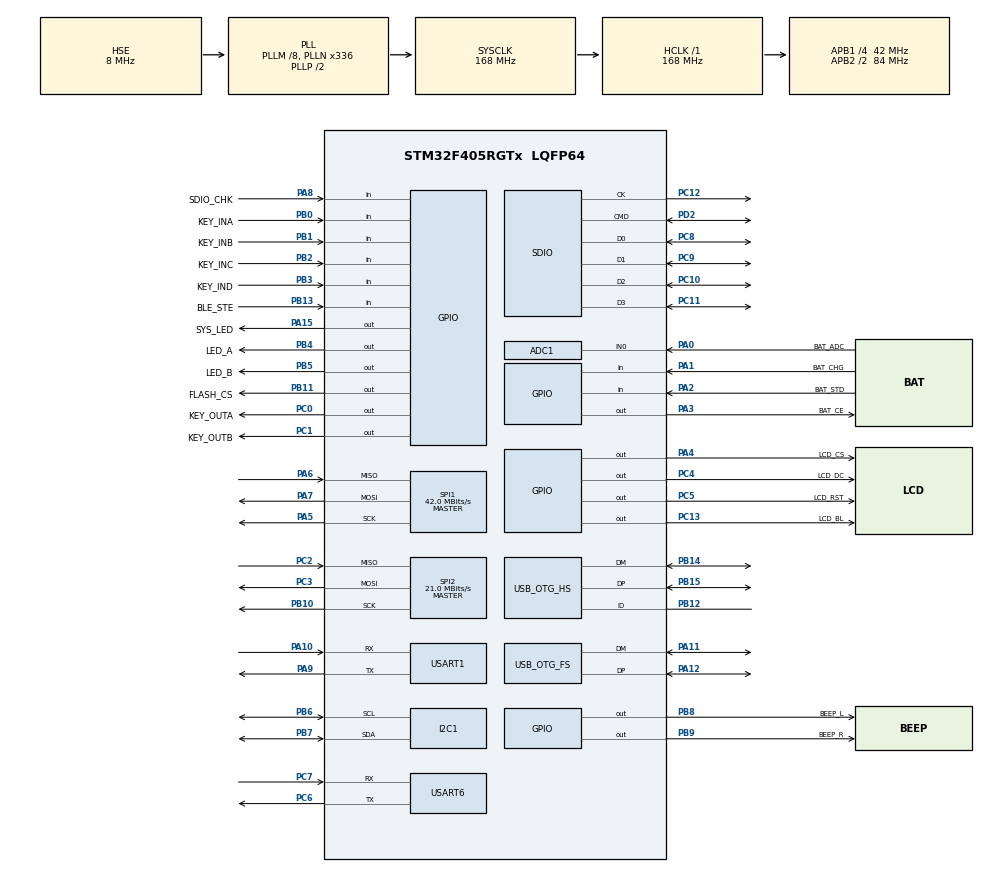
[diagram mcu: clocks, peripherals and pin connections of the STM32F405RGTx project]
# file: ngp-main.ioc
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ADC1.Channel-5\#ChannelRegularConversion=ADC_CHANNEL_0
ADC1.ClockPrescaler=ADC_CLOCK_SYNC_PCLK_DIV4
ADC1.ContinuousConvMode=DISABLE
ADC1.DMAContinuousRequests=DISABLE
ADC1.DataAlign=ADC_DATAALIGN_RIGHT
ADC1.DiscontinuousConvMode=DISABLE
ADC1.EOCSelection=ADC_EOC_SINGLE_CONV
ADC1.EnableAnalogWatchDog=false
ADC1.ExternalTrigConv=ADC_SOFTWARE_START
ADC1.ExternalTrigConvEdge=ADC_EXTERNALTRIGCONVEDGE_NONE
ADC1.InjNumberOfConversion=0
ADC1.NbrOfConversion=1
ADC1.NbrOfConversionFlag=1
ADC1.Rank-5\#ChannelRegularConversion=1
ADC1.Resolution=ADC_RESOLUTION_12B
ADC1.SamplingTime-5\#ChannelRegularConversion=ADC_SAMPLETIME_3CYCLES
ADC1.ScanConvMode=DISABLE
ADC1.master=1
FATFS.BSP.number=1
FATFS0.BSP.STBoard=false
FATFS0.BSP.api=Unknown
FATFS0.BSP.instance=PA8
FATFS0.BSP.ip=GPIO
FATFS0.BSP.mode=Input
FATFS0.BSP.name=Detect_SDIO
FATFS0.BSP.solution=PA8
Mcu.Family=STM32F4
Mcu.Name=STM32F405RGTx
Mcu.Package=LQFP64
NVIC.OTG_FS_IRQn=true\:0\:0\:false\:false\:true\:false
NVIC.PriorityGroup=NVIC_PRIORITYGROUP_4
NVIC.TIM1_UP_TIM10_IRQn=true\:0\:0\:false\:false\:true\:true
PA0-WKUP.GPIO_Label=BAT_ADC
PA0-WKUP.Signal=ADCx_IN0
PA1.GPIO_Label=BAT_CHG
PA1.GPIO_PuPd=GPIO_PULLUP
PA1.Signal=GPIO_Input
PA10.Mode=Asynchronous
PA10.Signal=USART1_RX
PA11.Mode=Device_Only
PA11.Signal=USB_OTG_FS_DM
PA12.Mode=Device_Only
PA12.Signal=USB_OTG_FS_DP
PA13.Mode=Serial_Wire
PA13.Signal=SYS_JTMS-SWDIO
PA14.Mode=Serial_Wire
PA14.Signal=SYS_JTCK-SWCLK
PA15.GPIO_Label=SYS_LED
PA15.GPIO_Speed=GPIO_SPEED_FREQ_VERY_HIGH
PA15.Signal=GPIO_Output
PA2.GPIO_Label=BAT_STD
PA2.GPIO_PuPd=GPIO_PULLUP
PA2.Signal=GPIO_Input
PA3.GPIO_Label=BAT_CE
PA3.GPIO_Speed=GPIO_SPEED_FREQ_VERY_HIGH
PA3.PinState=GPIO_PIN_SET
PA3.Signal=GPIO_Output
PA4.GPIO_Label=LCD_CS
PA4.GPIO_Speed=GPIO_SPEED_FREQ_VERY_HIGH
PA4.PinState=GPIO_PIN_SET
PA4.Signal=GPIO_Output
PA5.Mode=Full_Duplex_Master
PA5.Signal=SPI1_SCK
PA6.Mode=Full_Duplex_Master
PA6.Signal=SPI1_MISO
PA7.Mode=Full_Duplex_Master
PA7.Signal=SPI1_MOSI
PA8.GPIO_Label=SDIO_CHK
PA8.Signal=GPIO_Input
PA9.Mode=Asynchronous
PA9.Signal=USART1_TX
PB0.GPIO_Label=KEY_INA
PB0.GPIO_PuPd=GPIO_PULLUP
PB0.Signal=GPIO_Input
PB1.GPIO_Label=KEY_INB
PB1.GPIO_PuPd=GPIO_PULLUP
PB1.Signal=GPIO_Input
PB10.Mode=Full_Duplex_Master
PB10.Signal=SPI2_SCK
PB11.GPIO_Label=FLASH_CS
PB11.PinState=GPIO_PIN_SET
PB11.Signal=GPIO_Output
PB12.Mode=OTG/Dual-Role-Device-FS
PB12.Signal=USB_OTG_HS_ID
PB13.GPIO_Label=BLE_STE
PB13.GPIO_PuPd=GPIO_PULLUP
PB13.Signal=GPIO_Input
PB14.Mode=OTG/Dual-Role-Device-FS
PB14.Signal=USB_OTG_HS_DM
PB15.Mode=OTG/Dual-Role-Device-FS
PB15.Signal=USB_OTG_HS_DP
PB2.GPIO_Label=KEY_INC
PB2.GPIO_PuPd=GPIO_PULLUP
PB2.Signal=GPIO_Input
PB3.GPIO_Label=KEY_IND
PB3.GPIO_PuPd=GPIO_PULLUP
PB3.Signal=GPIO_Input
PB4.GPIO_Label=LED_A
PB4.GPIO_Speed=GPIO_SPEED_FREQ_VERY_HIGH
PB4.Signal=GPIO_Output
PB5.GPIO_Label=LED_B
PB5.GPIO_Speed=GPIO_SPEED_FREQ_VERY_HIGH
PB5.Signal=GPIO_Output
PB6.Mode=I2C
PB6.Signal=I2C1_SCL
PB7.Mode=I2C
PB7.Signal=I2C1_SDA
PB8.GPIO_Label=BEEP_L
PB8.GPIO_Speed=GPIO_SPEED_FREQ_VERY_HIGH
PB8.Signal=GPIO_Output
PB9.GPIO_Label=BEEP_R
PB9.GPIO_Speed=GPIO_SPEED_FREQ_VERY_HIGH
PB9.Signal=GPIO_Output
PC0.GPIO_Label=KEY_OUTA
PC0.GPIO_Speed=GPIO_SPEED_FREQ_VERY_HIGH
PC0.PinState=GPIO_PIN_SET
PC0.Signal=GPIO_Output
PC1.GPIO_Label=KEY_OUTB
PC1.GPIO_Speed=GPIO_SPEED_FREQ_VERY_HIGH
PC1.PinState=GPIO_PIN_SET
PC1.Signal=GPIO_Output
PC10.Mode=SD_4_bits_Wide_bus
PC10.Signal=SDIO_D2
PC11.Mode=SD_4_bits_Wide_bus
PC11.Signal=SDIO_D3
PC12.Mode=SD_4_bits_Wide_bus
PC12.Signal=SDIO_CK
PC13-ANTI_TAMP.GPIO_Label=LCD_BL
PC13-ANTI_TAMP.Signal=GPIO_Output
PC14-OSC32_IN.Mode=LSE-External-Oscillator
PC14-OSC32_IN.Signal=RCC_OSC32_IN
PC15-OSC32_OUT.Mode=LSE-External-Oscillator
PC15-OSC32_OUT.Signal=RCC_OSC32_OUT
PC2.Mode=Full_Duplex_Master
PC2.Signal=SPI2_MISO
PC3.Mode=Full_Duplex_Master
PC3.Signal=SPI2_MOSI
PC4.GPIO_Label=LCD_DC
PC4.GPIO_Speed=GPIO_SPEED_FREQ_VERY_HIGH
PC4.PinState=GPIO_PIN_SET
PC4.Signal=GPIO_Output
PC5.GPIO_Label=LCD_RST
PC5.GPIO_Speed=GPIO_SPEED_FREQ_VERY_HIGH
PC5.PinState=GPIO_PIN_SET
PC5.Signal=GPIO_Output
PC6.Mode=Asynchronous
PC6.Signal=USART6_TX
PC7.Mode=Asynchronous
PC7.Signal=USART6_RX
PC8.Mode=SD_4_bits_Wide_bus
PC8.Signal=SDIO_D0
PC9.Mode=SD_4_bits_Wide_bus
PC9.Signal=SDIO_D1
PD2.Mode=SD_4_bits_Wide_bus
PD2.Signal=SDIO_CMD
PH0-OSC_IN.Mode=HSE-External-Oscillator
PH0-OSC_IN.Signal=RCC_OSC_IN
PH1-OSC_OUT.Mode=HSE-External-Oscillator
PH1-OSC_OUT.Signal=RCC_OSC_OUT
ProjectManager.HeapSize=0x200
ProjectManager.StackSize=0x400
ProjectManager.TargetToolchain=SW4STM32
RCC.48MHZClocksFreq_Value=48000000
RCC.AHBFreq_Value=168000000
RCC.APB1CLKDivider=RCC_HCLK_DIV4
RCC.APB1Freq_Value=42000000
RCC.APB1TimFreq_Value=84000000
RCC.APB2CLKDivider=RCC_HCLK_DIV2
RCC.APB2Freq_Value=84000000
RCC.APB2TimFreq_Value=168000000
RCC.CortexFreq_Value=168000000
RCC.HCLKFreq_Value=168000000
RCC.HSE_VALUE=8000000
RCC.HSI_VALUE=16000000
RCC.PLLM=8
RCC.PLLN=336
RCC.PLLQ=7
RCC.RCC_RTC_Clock_Source=RCC_RTCCLKSOURCE_LSE
RCC.RCC_RTC_Clock_SourceVirtual=RCC_RTCCLKSOURCE_LSE
RCC.SYSCLKFreq_VALUE=168000000
RCC.SYSCLKSource=RCC_SYSCLKSOURCE_PLLCLK
RCC.VCOOutputFreq_Value=336000000
SH.ADCx_IN0.0=ADC1_IN0,IN0
SPI1.CalculateBaudRate=42.0 MBits/s
SPI1.Direction=SPI_DIRECTION_2LINES
SPI1.Mode=SPI_MODE_MASTER
SPI1.VirtualType=VM_MASTER
SPI2.BaudRatePrescaler=SPI_BAUDRATEPRESCALER_2
SPI2.CalculateBaudRate=21.0 MBits/s
SPI2.Direction=SPI_DIRECTION_2LINES
SPI2.Mode=SPI_MODE_MASTER
SPI2.VirtualType=VM_MASTER
TIM10.Period=239
TIM10.Prescaler=7
USART1.VirtualMode=VM_ASYNC
USART6.VirtualMode=VM_ASYNC
USB_DEVICE.CLASS_NAME_FS=MSC
USB_DEVICE.CONFIGURATION_STRING_MSC_FS=NGP Config
USB_DEVICE.INTERFACE_STRING_MSC_FS=NGP Interface
USB_DEVICE.MANUFACTURER_STRING-MSC_FS=NSDN
USB_DEVICE.PRODUCT_STRING_MSC_FS=NyaGame Portable v2.0
USB_DEVICE.VirtualMode-MSC_FS=Msc
USB_DEVICE.VirtualModeFS=Msc_FS
USB_OTG_FS.VirtualMode=Device_Only
VP_FATFS_VS_Generic.Mode=User_defined
VP_FATFS_VS_SDIO.Mode=SDIO
VP_RTC_VS_RTC_Activate.Mode=RTC_Enabled
VP_RTC_VS_RTC_Calendar.Mode=RTC_Calendar
VP_TIM10_VS_ClockSourceINT.Mode=Enable_Timer
VP_USB_DEVICE_VS_USB_DEVICE_MSC_FS.Mode=MSC_FS
board=custom

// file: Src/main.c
/* USER CODE BEGIN Header */
/**
  ******************************************************************************
  * @file           : main.c
  * @brief          : Main program body
  ******************************************************************************
  * This notice applies to any and all portions of this file
  * that are not between comment pairs USER CODE BEGIN and
  * USER CODE END. Other portions of this file, whether
  * inserted by the user or by software development tools
  * are owned by their respective copyright owners.
  *
  * Copyright (c) 2019 STMicroelectronics International N.V.
  * All rights reserved.
  *
  * Redistribution and use in source and binary forms, with or without
  * modification, are permitted, provided that the following conditions are met:
  *
  * 1. Redistribution of source code must retain the above copyright notice,
  *    this list of conditions and the following disclaimer.
  * 2. Redistributions in binary form must reproduce the above copyright notice,
  *    this list of conditions and the following disclaimer in the documentation
  *    and/or other materials provided with the distribution.
  * 3. Neither the name of STMicroelectronics nor the names of other
  *    contributors to this software may be used to endorse or promote products
  *    derived from this software without specific written permission.
  * 4. This software, including modifications and/or derivative works of this
  *    software, must execute solely and exclusively on microcontroller or
  *    microprocessor devices manufactured by or for STMicroelectronics.
  * 5. Redistribution and use of this software other than as permitted under
  *    this license is void and will automatically terminate your rights under
  *    this license.
  *
  * THIS SOFTWARE IS PROVIDED BY STMICROELECTRONICS AND CONTRIBUTORS "AS IS"
  * AND ANY EXPRESS, IMPLIED OR STATUTORY WARRANTIES, INCLUDING, BUT NOT
  * LIMITED TO, THE IMPLIED WARRANTIES OF MERCHANTABILITY, FITNESS FOR A
  * PARTICULAR PURPOSE AND NON-INFRINGEMENT OF THIRD PARTY INTELLECTUAL PROPERTY
  * RIGHTS ARE DISCLAIMED TO THE FULLEST EXTENT PERMITTED BY LAW. IN NO EVENT
  * SHALL STMICROELECTRONICS OR CONTRIBUTORS BE LIABLE FOR ANY DIRECT, INDIRECT,
  * INCIDENTAL, SPECIAL, EXEMPLARY, OR CONSEQUENTIAL DAMAGES (INCLUDING, BUT NOT
  * LIMITED TO, PROCUREMENT OF SUBSTITUTE GOODS OR SERVICES; LOSS OF USE, DATA,
  * OR PROFITS; OR BUSINESS INTERRUPTION) HOWEVER CAUSED AND ON ANY THEORY OF
  * LIABILITY, WHETHER IN CONTRACT, STRICT LIABILITY, OR TORT (INCLUDING
  * NEGLIGENCE OR OTHERWISE) ARISING IN ANY WAY OUT OF THE USE OF THIS SOFTWARE,
  * EVEN IF ADVISED OF THE POSSIBILITY OF SUCH DAMAGE.
  *
  ******************************************************************************
  */
/* USER CODE END Header */

#include "main.h"
#include "fatfs.h"
#include "usb_device.h"

/* USER CODE BEGIN Includes */
#include "ngp_bios.h"
/* USER CODE END Includes */

ADC_HandleTypeDef hadc1;

I2C_HandleTypeDef hi2c1;

RTC_HandleTypeDef hrtc;

SD_HandleTypeDef hsd;

SPI_HandleTypeDef hspi1;
SPI_HandleTypeDef hspi2;

TIM_HandleTypeDef htim10;

UART_HandleTypeDef huart1;
UART_HandleTypeDef huart6;

/* USER CODE BEGIN PV */
/* Private variables ---------------------------------------------------------*/

/* USER CODE END PV */

void SystemClock_Config(void);
static void MX_GPIO_Init(void);
static void MX_SDIO_SD_Init(void);
static void MX_SPI2_Init(void);
static void MX_I2C1_Init(void);
static void MX_USART1_UART_Init(void);
static void MX_USART6_UART_Init(void);
static void MX_ADC1_Init(void);
static void MX_USB_OTG_HS_USB_Init(void);
static void MX_RTC_Init(void);
static void MX_TIM10_Init(void);
static void MX_SPI1_Init(void);
/* USER CODE BEGIN PFP */
/* Private function prototypes -----------------------------------------------*/

/* USER CODE END PFP */

int main(void)
{

  /* MCU Configuration--------------------------------------------------------*/

  /* Reset of all peripherals, Initializes the Flash interface and the Systick. */
  HAL_Init();

  /* Configure the system clock */
  SystemClock_Config();

  /* Initialize all configured peripherals */
  MX_GPIO_Init();
  MX_SDIO_SD_Init();
  MX_SPI2_Init();
  MX_I2C1_Init();
  MX_USART1_UART_Init();
  MX_USART6_UART_Init();
  MX_ADC1_Init();
  MX_USB_OTG_HS_USB_Init();
  MX_RTC_Init();
  MX_USB_DEVICE_Init();
  MX_FATFS_Init();
  MX_TIM10_Init();
  MX_SPI1_Init();
  /* USER CODE BEGIN 2 */
  setup();
  /* USER CODE END 2 */

  /* Infinite loop */
  /* USER CODE BEGIN WHILE */
  while (1) loop();
    /* USER CODE END WHILE */

}

void SystemClock_Config(void)
{
  RCC_OscInitTypeDef RCC_OscInitStruct = {0};
  RCC_ClkInitTypeDef RCC_ClkInitStruct = {0};
  RCC_PeriphCLKInitTypeDef PeriphClkInitStruct = {0};

  /**Configure the main internal regulator output voltage
  */
  __HAL_RCC_PWR_CLK_ENABLE();
  __HAL_PWR_VOLTAGESCALING_CONFIG(PWR_REGULATOR_VOLTAGE_SCALE1);
  /**Initializes the CPU, AHB and APB busses clocks
  */
  RCC_OscInitStruct.OscillatorType = RCC_OSCILLATORTYPE_HSE|RCC_OSCILLATORTYPE_LSE;
  RCC_OscInitStruct.HSEState = RCC_HSE_ON;
  RCC_OscInitStruct.LSEState = RCC_LSE_ON;
  RCC_OscInitStruct.PLL.PLLState = RCC_PLL_ON;
  RCC_OscInitStruct.PLL.PLLSource = RCC_PLLSOURCE_HSE;
  RCC_OscInitStruct.PLL.PLLM = 8;
  RCC_OscInitStruct.PLL.PLLN = 336;
  RCC_OscInitStruct.PLL.PLLP = RCC_PLLP_DIV2;
  RCC_OscInitStruct.PLL.PLLQ = 7;
  if (HAL_RCC_OscConfig(&RCC_OscInitStruct) != HAL_OK)
  {
    Error_Handler();
  }
  /**Initializes the CPU, AHB and APB busses clocks
  */
  RCC_ClkInitStruct.ClockType = RCC_CLOCKTYPE_HCLK|RCC_CLOCKTYPE_SYSCLK
                              |RCC_CLOCKTYPE_PCLK1|RCC_CLOCKTYPE_PCLK2;
  RCC_ClkInitStruct.SYSCLKSource = RCC_SYSCLKSOURCE_PLLCLK;
  RCC_ClkInitStruct.AHBCLKDivider = RCC_SYSCLK_DIV1;
  RCC_ClkInitStruct.APB1CLKDivider = RCC_HCLK_DIV4;
  RCC_ClkInitStruct.APB2CLKDivider = RCC_HCLK_DIV2;

  if (HAL_RCC_ClockConfig(&RCC_ClkInitStruct, FLASH_LATENCY_5) != HAL_OK)
  {
    Error_Handler();
  }
  PeriphClkInitStruct.PeriphClockSelection = RCC_PERIPHCLK_RTC;
  PeriphClkInitStruct.RTCClockSelection = RCC_RTCCLKSOURCE_LSE;
  if (HAL_RCCEx_PeriphCLKConfig(&PeriphClkInitStruct) != HAL_OK)
  {
    Error_Handler();
  }
}

static void MX_ADC1_Init(void)
{

  ADC_ChannelConfTypeDef sConfig = {0};

  /**Configure the global features of the ADC (Clock, Resolution, Data Alignment and number of conversion)
  */
  hadc1.Instance = ADC1;
  hadc1.Init.ClockPrescaler = ADC_CLOCK_SYNC_PCLK_DIV4;
  hadc1.Init.Resolution = ADC_RESOLUTION_12B;
  hadc1.Init.ScanConvMode = DISABLE;
  hadc1.Init.ContinuousConvMode = DISABLE;
  hadc1.Init.DiscontinuousConvMode = DISABLE;
  hadc1.Init.ExternalTrigConvEdge = ADC_EXTERNALTRIGCONVEDGE_NONE;
  hadc1.Init.ExternalTrigConv = ADC_SOFTWARE_START;
  hadc1.Init.DataAlign = ADC_DATAALIGN_RIGHT;
  hadc1.Init.NbrOfConversion = 1;
  hadc1.Init.DMAContinuousRequests = DISABLE;
  hadc1.Init.EOCSelection = ADC_EOC_SINGLE_CONV;
  if (HAL_ADC_Init(&hadc1) != HAL_OK)
  {
    Error_Handler();
  }
  /**Configure for the selected ADC regular channel its corresponding rank in the sequencer and its sample time.
  */
  sConfig.Channel = ADC_CHANNEL_0;
  sConfig.Rank = 1;
  sConfig.SamplingTime = ADC_SAMPLETIME_3CYCLES;
  if (HAL_ADC_ConfigChannel(&hadc1, &sConfig) != HAL_OK)
  {
    Error_Handler();
  }

}

static void MX_I2C1_Init(void)
{

  hi2c1.Instance = I2C1;
  hi2c1.Init.ClockSpeed = 100000;
  hi2c1.Init.DutyCycle = I2C_DUTYCYCLE_2;
  hi2c1.Init.OwnAddress1 = 0;
  hi2c1.Init.AddressingMode = I2C_ADDRESSINGMODE_7BIT;
  hi2c1.Init.DualAddressMode = I2C_DUALADDRESS_DISABLE;
  hi2c1.Init.OwnAddress2 = 0;
  hi2c1.Init.GeneralCallMode = I2C_GENERALCALL_DISABLE;
  hi2c1.Init.NoStretchMode = I2C_NOSTRETCH_DISABLE;
  if (HAL_I2C_Init(&hi2c1) != HAL_OK)
  {
    Error_Handler();
  }

}

static void MX_RTC_Init(void)
{

  RTC_TimeTypeDef sTime = {0};
  RTC_DateTypeDef sDate = {0};

  /**Initialize RTC Only
  */
  hrtc.Instance = RTC;
  hrtc.Init.HourFormat = RTC_HOURFORMAT_24;
  hrtc.Init.AsynchPrediv = 127;
  hrtc.Init.SynchPrediv = 255;
  hrtc.Init.OutPut = RTC_OUTPUT_DISABLE;
  hrtc.Init.OutPutPolarity = RTC_OUTPUT_POLARITY_HIGH;
  hrtc.Init.OutPutType = RTC_OUTPUT_TYPE_OPENDRAIN;
  if (HAL_RTC_Init(&hrtc) != HAL_OK)
  {
    Error_Handler();
  }

  /**Initialize RTC and set the Time and Date
  */
  sTime.Hours = 0x0;
  sTime.Minutes = 0x0;
  sTime.Seconds = 0x0;
  sTime.DayLightSaving = RTC_DAYLIGHTSAVING_NONE;
  sTime.StoreOperation = RTC_STOREOPERATION_RESET;
  if (HAL_RTC_SetTime(&hrtc, &sTime, RTC_FORMAT_BCD) != HAL_OK)
  {
    Error_Handler();
  }
  sDate.WeekDay = RTC_WEEKDAY_MONDAY;
  sDate.Month = RTC_MONTH_JANUARY;
  sDate.Date = 0x1;
  sDate.Year = 0x0;

  if (HAL_RTC_SetDate(&hrtc, &sDate, RTC_FORMAT_BCD) != HAL_OK)
  {
    Error_Handler();
  }

}

static void MX_SDIO_SD_Init(void)
{

  hsd.Instance = SDIO;
  hsd.Init.ClockEdge = SDIO_CLOCK_EDGE_RISING;
  hsd.Init.ClockBypass = SDIO_CLOCK_BYPASS_DISABLE;
  hsd.Init.ClockPowerSave = SDIO_CLOCK_POWER_SAVE_DISABLE;
  hsd.Init.BusWide = SDIO_BUS_WIDE_1B;
  hsd.Init.HardwareFlowControl = SDIO_HARDWARE_FLOW_CONTROL_DISABLE;
  hsd.Init.ClockDiv = 0;

}

static void MX_SPI1_Init(void)
{

  /* SPI1 parameter configuration*/
  hspi1.Instance = SPI1;
  hspi1.Init.Mode = SPI_MODE_MASTER;
  hspi1.Init.Direction = SPI_DIRECTION_2LINES;
  hspi1.Init.DataSize = SPI_DATASIZE_8BIT;
  hspi1.Init.CLKPolarity = SPI_POLARITY_LOW;
  hspi1.Init.CLKPhase = SPI_PHASE_1EDGE;
  hspi1.Init.NSS = SPI_NSS_SOFT;
  hspi1.Init.BaudRatePrescaler = SPI_BAUDRATEPRESCALER_2;
  hspi1.Init.FirstBit = SPI_FIRSTBIT_MSB;
  hspi1.Init.TIMode = SPI_TIMODE_DISABLE;
  hspi1.Init.CRCCalculation = SPI_CRCCALCULATION_DISABLE;
  hspi1.Init.CRCPolynomial = 10;
  if (HAL_SPI_Init(&hspi1) != HAL_OK)
  {
    Error_Handler();
  }

}

static void MX_SPI2_Init(void)
{

  /* SPI2 parameter configuration*/
  hspi2.Instance = SPI2;
  hspi2.Init.Mode = SPI_MODE_MASTER;
  hspi2.Init.Direction = SPI_DIRECTION_2LINES;
  hspi2.Init.DataSize = SPI_DATASIZE_8BIT;
  hspi2.Init.CLKPolarity = SPI_POLARITY_LOW;
  hspi2.Init.CLKPhase = SPI_PHASE_1EDGE;
  hspi2.Init.NSS = SPI_NSS_SOFT;
  hspi2.Init.BaudRatePrescaler = SPI_BAUDRATEPRESCALER_2;
  hspi2.Init.FirstBit = SPI_FIRSTBIT_MSB;
  hspi2.Init.TIMode = SPI_TIMODE_DISABLE;
  hspi2.Init.CRCCalculation = SPI_CRCCALCULATION_DISABLE;
  hspi2.Init.CRCPolynomial = 10;
  if (HAL_SPI_Init(&hspi2) != HAL_OK)
  {
    Error_Handler();
  }

}

static void MX_TIM10_Init(void)
{

  htim10.Instance = TIM10;
  htim10.Init.Prescaler = 7;
  htim10.Init.CounterMode = TIM_COUNTERMODE_UP;
  htim10.Init.Period = 239;
  htim10.Init.ClockDivision = TIM_CLOCKDIVISION_DIV1;
  if (HAL_TIM_Base_Init(&htim10) != HAL_OK)
  {
    Error_Handler();
  }

}

static void MX_USART1_UART_Init(void)
{

  huart1.Instance = USART1;
  huart1.Init.BaudRate = 115200;
  huart1.Init.WordLength = UART_WORDLENGTH_8B;
  huart1.Init.StopBits = UART_STOPBITS_1;
  huart1.Init.Parity = UART_PARITY_NONE;
  huart1.Init.Mode = UART_MODE_TX_RX;
  huart1.Init.HwFlowCtl = UART_HWCONTROL_NONE;
  huart1.Init.OverSampling = UART_OVERSAMPLING_16;
  if (HAL_UART_Init(&huart1) != HAL_OK)
  {
    Error_Handler();
  }

}

static void MX_USART6_UART_Init(void)
{

  huart6.Instance = USART6;
  huart6.Init.BaudRate = 115200;
  huart6.Init.WordLength = UART_WORDLENGTH_8B;
  huart6.Init.StopBits = UART_STOPBITS_1;
  huart6.Init.Parity = UART_PARITY_NONE;
  huart6.Init.Mode = UART_MODE_TX_RX;
  huart6.Init.HwFlowCtl = UART_HWCONTROL_NONE;
  huart6.Init.OverSampling = UART_OVERSAMPLING_16;
  if (HAL_UART_Init(&huart6) != HAL_OK)
  {
    Error_Handler();
  }

}

static void MX_USB_OTG_HS_USB_Init(void)
{

}

static void MX_GPIO_Init(void)
{
  GPIO_InitTypeDef GPIO_InitStruct = {0};

  /* GPIO Ports Clock Enable */
  __HAL_RCC_GPIOC_CLK_ENABLE();
  __HAL_RCC_GPIOH_CLK_ENABLE();
  __HAL_RCC_GPIOA_CLK_ENABLE();
  __HAL_RCC_GPIOB_CLK_ENABLE();
  __HAL_RCC_GPIOD_CLK_ENABLE();

  /*Configure GPIO pin Output Level */
  HAL_GPIO_WritePin(LCD_BL_GPIO_Port, LCD_BL_Pin, GPIO_PIN_RESET);

  /*Configure GPIO pin Output Level */
  HAL_GPIO_WritePin(GPIOC, KEY_OUTA_Pin|KEY_OUTB_Pin|LCD_DC_Pin|LCD_RST_Pin, GPIO_PIN_SET);

  /*Configure GPIO pin Output Level */
  HAL_GPIO_WritePin(GPIOA, BAT_CE_Pin|LCD_CS_Pin, GPIO_PIN_SET);

  /*Configure GPIO pin Output Level */
  HAL_GPIO_WritePin(FLASH_CS_GPIO_Port, FLASH_CS_Pin, GPIO_PIN_SET);

  /*Configure GPIO pin Output Level */
  HAL_GPIO_WritePin(SYS_LED_GPIO_Port, SYS_LED_Pin, GPIO_PIN_RESET);

  /*Configure GPIO pin Output Level */
  HAL_GPIO_WritePin(GPIOB, LED_A_Pin|LED_B_Pin|BEEP_L_Pin|BEEP_R_Pin, GPIO_PIN_RESET);

  /*Configure GPIO pin : LCD_BL_Pin */
  GPIO_InitStruct.Pin = LCD_BL_Pin;
  GPIO_InitStruct.Mode = GPIO_MODE_OUTPUT_PP;
  GPIO_InitStruct.Pull = GPIO_NOPULL;
  GPIO_InitStruct.Speed = GPIO_SPEED_FREQ_LOW;
  HAL_GPIO_Init(LCD_BL_GPIO_Port, &GPIO_InitStruct);

  /*Configure GPIO pins : KEY_OUTA_Pin KEY_OUTB_Pin LCD_DC_Pin LCD_RST_Pin */
  GPIO_InitStruct.Pin = KEY_OUTA_Pin|KEY_OUTB_Pin|LCD_DC_Pin|LCD_RST_Pin;
  GPIO_InitStruct.Mode = GPIO_MODE_OUTPUT_PP;
  GPIO_InitStruct.Pull = GPIO_NOPULL;
  GPIO_InitStruct.Speed = GPIO_SPEED_FREQ_VERY_HIGH;
  HAL_GPIO_Init(GPIOC, &GPIO_InitStruct);

  /*Configure GPIO pins : BAT_CHG_Pin BAT_STD_Pin */
  GPIO_InitStruct.Pin = BAT_CHG_Pin|BAT_STD_Pin;
  GPIO_InitStruct.Mode = GPIO_MODE_INPUT;
  GPIO_InitStruct.Pull = GPIO_PULLUP;
  HAL_GPIO_Init(GPIOA, &GPIO_InitStruct);

  /*Configure GPIO pins : BAT_CE_Pin LCD_CS_Pin SYS_LED_Pin */
  GPIO_InitStruct.Pin = BAT_CE_Pin|LCD_CS_Pin|SYS_LED_Pin;
  GPIO_InitStruct.Mode = GPIO_MODE_OUTPUT_PP;
  GPIO_InitStruct.Pull = GPIO_NOPULL;
  GPIO_InitStruct.Speed = GPIO_SPEED_FREQ_VERY_HIGH;
  HAL_GPIO_Init(GPIOA, &GPIO_InitStruct);

  /*Configure GPIO pins : KEY_INA_Pin KEY_INB_Pin KEY_INC_Pin BLE_STE_Pin
                           KEY_IND_Pin */
  GPIO_InitStruct.Pin = KEY_INA_Pin|KEY_INB_Pin|KEY_INC_Pin|BLE_STE_Pin
                          |KEY_IND_Pin;
  GPIO_InitStruct.Mode = GPIO_MODE_INPUT;
  GPIO_InitStruct.Pull = GPIO_PULLUP;
  HAL_GPIO_Init(GPIOB, &GPIO_InitStruct);

  /*Configure GPIO pin : FLASH_CS_Pin */
  GPIO_InitStruct.Pin = FLASH_CS_Pin;
  GPIO_InitStruct.Mode = GPIO_MODE_OUTPUT_PP;
  GPIO_InitStruct.Pull = GPIO_NOPULL;
  GPIO_InitStruct.Speed = GPIO_SPEED_FREQ_LOW;
  HAL_GPIO_Init(FLASH_CS_GPIO_Port, &GPIO_InitStruct);

  /*Configure GPIO pins : PB12 PB14 PB15 */
  GPIO_InitStruct.Pin = GPIO_PIN_12|GPIO_PIN_14|GPIO_PIN_15;
  GPIO_InitStruct.Mode = GPIO_MODE_AF_PP;
  GPIO_InitStruct.Pull = GPIO_NOPULL;
  GPIO_InitStruct.Speed = GPIO_SPEED_FREQ_VERY_HIGH;
  GPIO_InitStruct.Alternate = GPIO_AF12_OTG_HS_FS;
  HAL_GPIO_Init(GPIOB, &GPIO_InitStruct);

  /*Configure GPIO pin : SDIO_CHK_Pin */
  GPIO_InitStruct.Pin = SDIO_CHK_Pin;
  GPIO_InitStruct.Mode = GPIO_MODE_INPUT;
  GPIO_InitStruct.Pull = GPIO_NOPULL;
  HAL_GPIO_Init(SDIO_CHK_GPIO_Port, &GPIO_InitStruct);

  /*Configure GPIO pins : LED_A_Pin LED_B_Pin BEEP_L_Pin BEEP_R_Pin */
  GPIO_InitStruct.Pin = LED_A_Pin|LED_B_Pin|BEEP_L_Pin|BEEP_R_Pin;
  GPIO_InitStruct.Mode = GPIO_MODE_OUTPUT_PP;
  GPIO_InitStruct.Pull = GPIO_NOPULL;
  GPIO_InitStruct.Speed = GPIO_SPEED_FREQ_VERY_HIGH;
  HAL_GPIO_Init(GPIOB, &GPIO_InitStruct);

}

void Error_Handler(void)
{
  while(1)
  {
  }
}

/************************ (C) COPYRIGHT STMicroelectronics *****END OF FILE****/
